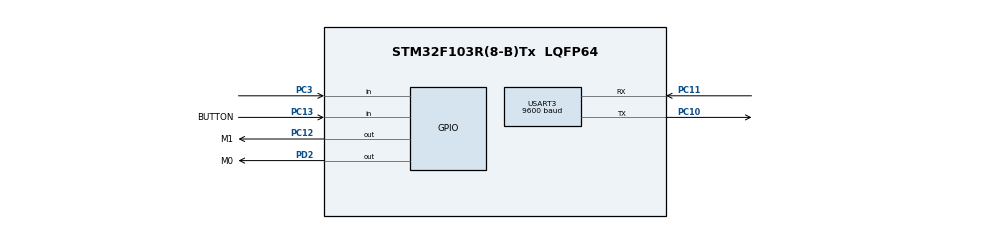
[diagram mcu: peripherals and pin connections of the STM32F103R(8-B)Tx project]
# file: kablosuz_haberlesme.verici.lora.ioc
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Mcu.Family=STM32F1
Mcu.Name=STM32F103R(8-B)Tx
Mcu.Package=LQFP64
NVIC.PriorityGroup=NVIC_PRIORITYGROUP_4
PA13.Mode=Serial_Wire
PA13.Signal=SYS_JTMS-SWDIO
PA14.Mode=Serial_Wire
PA14.Signal=SYS_JTCK-SWCLK
PC10.Mode=Asynchronous
PC10.Signal=USART3_TX
PC11.Mode=Asynchronous
PC11.Signal=USART3_RX
PC12.GPIO_Label=M1
PC12.Signal=GPIO_Output
PC13-TAMPER-RTC.GPIO_Label=BUTTON
PC13-TAMPER-RTC.Signal=GPIO_Input
PC3.Signal=GPIO_Input
PD0-OSC_IN.Mode=HSE-External-Oscillator
PD0-OSC_IN.Signal=RCC_OSC_IN
PD1-OSC_OUT.Mode=HSE-External-Oscillator
PD1-OSC_OUT.Signal=RCC_OSC_OUT
PD2.GPIO_Label=M0
PD2.Signal=GPIO_Output
ProjectManager.HeapSize=0x200
ProjectManager.StackSize=0x400
ProjectManager.TargetToolchain=STM32CubeIDE
RCC.APB1Freq_Value=8000000
RCC.APB2Freq_Value=8000000
USART3.BaudRate=9600
USART3.VirtualMode=VM_ASYNC
board=custom

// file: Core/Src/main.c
/* USER CODE BEGIN Header */
/**
  ******************************************************************************
  * @file           : main.c
  * @brief          : Main program body
  ******************************************************************************
  * @attention
  *
  * Copyright (c) 2022 STMicroelectronics.
  * All rights reserved.
  *
  * This software is licensed under terms that can be found in the LICENSE file
  * in the root directory of this software component.
  * If no LICENSE file comes with this software, it is provided AS-IS.
  *
  ******************************************************************************
  */
/* USER CODE END Header */
#include "main.h"

 UART_HandleTypeDef huart3;

void SystemClock_Config(void);
static void MX_GPIO_Init(void);
static void MX_USART3_UART_Init(void);

/* USER CODE BEGIN 0 */
uint8_t TxBuffer[1] = {0};
/* USER CODE END 0 */

int main(void)
{
  /* USER CODE BEGIN 1 */
	HAL_GPIO_WritePin(GPIOD, GPIO_PIN_2 , GPIO_PIN_RESET);
	HAL_GPIO_WritePin(GPIOC, GPIO_PIN_12, GPIO_PIN_RESET);
  /* USER CODE END 1 */

  /* MCU Configuration--------------------------------------------------------*/

  /* Reset of all peripherals, Initializes the Flash interface and the Systick. */
  HAL_Init();

  /* Configure the system clock */
  SystemClock_Config();

  /* Initialize all configured peripherals */
  MX_GPIO_Init();
  MX_USART3_UART_Init();
  /* USER CODE BEGIN 2 */
  int i=0;
  /* USER CODE END 2 */

  /* Infinite loop */
  while (1)
  {

    /* USER CODE BEGIN 3 */
	HAL_GPIO_WritePin(GPIOD, GPIO_PIN_2 , GPIO_PIN_RESET);
	HAL_GPIO_WritePin(GPIOC, GPIO_PIN_12, GPIO_PIN_RESET);
	HAL_Delay(10);

	for(i= 0; i< 125; i++){

		TxBuffer[0] = i;

		uint8_t SendBuf[4] = { 0x05, 0x01, 0x17 , TxBuffer[0]};
		HAL_UART_Transmit(&huart3,SendBuf,4,1000);
		HAL_Delay(1000);
	}

	if(i == 125){
		i = 0;
	}
  }
  /* USER CODE END 3 */
}

void SystemClock_Config(void)
{
  RCC_OscInitTypeDef RCC_OscInitStruct = {0};
  RCC_ClkInitTypeDef RCC_ClkInitStruct = {0};

  /** Initializes the RCC Oscillators according to the specified parameters
  * in the RCC_OscInitTypeDef structure.
  */
  RCC_OscInitStruct.OscillatorType = RCC_OSCILLATORTYPE_HSI;
  RCC_OscInitStruct.HSIState = RCC_HSI_ON;
  RCC_OscInitStruct.HSICalibrationValue = RCC_HSICALIBRATION_DEFAULT;
  RCC_OscInitStruct.PLL.PLLState = RCC_PLL_NONE;
  if (HAL_RCC_OscConfig(&RCC_OscInitStruct) != HAL_OK)
  {
    Error_Handler();
  }

  /** Initializes the CPU, AHB and APB buses clocks
  */
  RCC_ClkInitStruct.ClockType = RCC_CLOCKTYPE_HCLK|RCC_CLOCKTYPE_SYSCLK
                              |RCC_CLOCKTYPE_PCLK1|RCC_CLOCKTYPE_PCLK2;
  RCC_ClkInitStruct.SYSCLKSource = RCC_SYSCLKSOURCE_HSI;
  RCC_ClkInitStruct.AHBCLKDivider = RCC_SYSCLK_DIV1;
  RCC_ClkInitStruct.APB1CLKDivider = RCC_HCLK_DIV1;
  RCC_ClkInitStruct.APB2CLKDivider = RCC_HCLK_DIV1;

  if (HAL_RCC_ClockConfig(&RCC_ClkInitStruct, FLASH_LATENCY_0) != HAL_OK)
  {
    Error_Handler();
  }
}

static void MX_USART3_UART_Init(void)
{

  huart3.Instance = USART3;
  huart3.Init.BaudRate = 9600;
  huart3.Init.WordLength = UART_WORDLENGTH_8B;
  huart3.Init.StopBits = UART_STOPBITS_1;
  huart3.Init.Parity = UART_PARITY_NONE;
  huart3.Init.Mode = UART_MODE_TX_RX;
  huart3.Init.HwFlowCtl = UART_HWCONTROL_NONE;
  huart3.Init.OverSampling = UART_OVERSAMPLING_16;
  if (HAL_UART_Init(&huart3) != HAL_OK)
  {
    Error_Handler();
  }

}

static void MX_GPIO_Init(void)
{
  GPIO_InitTypeDef GPIO_InitStruct = {0};

  /* GPIO Ports Clock Enable */
  __HAL_RCC_GPIOC_CLK_ENABLE();
  __HAL_RCC_GPIOD_CLK_ENABLE();
  __HAL_RCC_GPIOA_CLK_ENABLE();

  /*Configure GPIO pin Output Level */
  HAL_GPIO_WritePin(M1_GPIO_Port, M1_Pin, GPIO_PIN_RESET);

  /*Configure GPIO pin Output Level */
  HAL_GPIO_WritePin(M0_GPIO_Port, M0_Pin, GPIO_PIN_RESET);

  /*Configure GPIO pins : BUTTON_Pin PC3 */
  GPIO_InitStruct.Pin = BUTTON_Pin|GPIO_PIN_3;
  GPIO_InitStruct.Mode = GPIO_MODE_INPUT;
  GPIO_InitStruct.Pull = GPIO_NOPULL;
  HAL_GPIO_Init(GPIOC, &GPIO_InitStruct);

  /*Configure GPIO pin : M1_Pin */
  GPIO_InitStruct.Pin = M1_Pin;
  GPIO_InitStruct.Mode = GPIO_MODE_OUTPUT_PP;
  GPIO_InitStruct.Pull = GPIO_NOPULL;
  GPIO_InitStruct.Speed = GPIO_SPEED_FREQ_LOW;
  HAL_GPIO_Init(M1_GPIO_Port, &GPIO_InitStruct);

  /*Configure GPIO pin : M0_Pin */
  GPIO_InitStruct.Pin = M0_Pin;
  GPIO_InitStruct.Mode = GPIO_MODE_OUTPUT_PP;
  GPIO_InitStruct.Pull = GPIO_NOPULL;
  GPIO_InitStruct.Speed = GPIO_SPEED_FREQ_LOW;
  HAL_GPIO_Init(M0_GPIO_Port, &GPIO_InitStruct);

}

void Error_Handler(void)
{
  __disable_irq();
  while (1)
  {
  }
}
